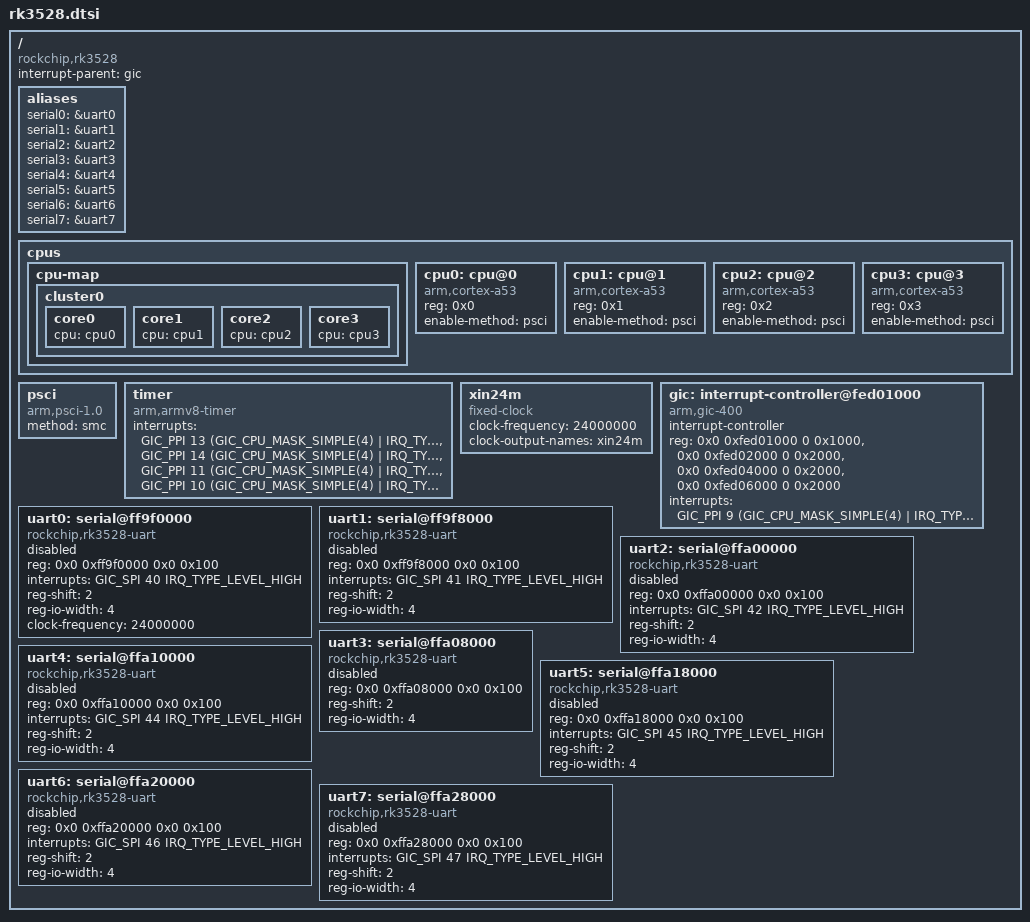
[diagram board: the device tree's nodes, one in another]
// SPDX-License-Identifier: (GPL-2.0+ OR MIT)
/*
 * Copyright (c) 2022 Rockchip Electronics Co., Ltd.
 * Copyright (c) 2024 Yao Zi <ziyao@disroot.org>
 */

#include <dt-bindings/interrupt-controller/arm-gic.h>
#include <dt-bindings/interrupt-controller/irq.h>

/ {
	compatible = "rockchip,rk3528";

	interrupt-parent = <&gic>;
	#address-cells = <2>;
	#size-cells = <2>;

	aliases {
		serial0 = &uart0;
		serial1 = &uart1;
		serial2 = &uart2;
		serial3 = &uart3;
		serial4 = &uart4;
		serial5 = &uart5;
		serial6 = &uart6;
		serial7 = &uart7;
	};

	cpus {
		#address-cells = <1>;
		#size-cells = <0>;

		cpu-map {
			cluster0 {
				core0 {
					cpu = <&cpu0>;
				};
				core1 {
					cpu = <&cpu1>;
				};
				core2 {
					cpu = <&cpu2>;
				};
				core3 {
					cpu = <&cpu3>;
				};
			};
		};

		cpu0: cpu@0 {
			device_type = "cpu";
			compatible = "arm,cortex-a53";
			reg = <0x0>;
			enable-method = "psci";
		};

		cpu1: cpu@1 {
			device_type = "cpu";
			compatible = "arm,cortex-a53";
			reg = <0x1>;
			enable-method = "psci";
		};

		cpu2: cpu@2 {
			device_type = "cpu";
			compatible = "arm,cortex-a53";
			reg = <0x2>;
			enable-method = "psci";
		};

		cpu3: cpu@3 {
			device_type = "cpu";
			compatible = "arm,cortex-a53";
			reg = <0x3>;
			enable-method = "psci";
		};
	};

	psci {
		compatible = "arm,psci-1.0", "arm,psci-0.2";
		method = "smc";
	};

	timer {
		compatible = "arm,armv8-timer";
		interrupts = <GIC_PPI 13 (GIC_CPU_MASK_SIMPLE(4) | IRQ_TYPE_LEVEL_LOW)>,
			     <GIC_PPI 14 (GIC_CPU_MASK_SIMPLE(4) | IRQ_TYPE_LEVEL_LOW)>,
			     <GIC_PPI 11 (GIC_CPU_MASK_SIMPLE(4) | IRQ_TYPE_LEVEL_LOW)>,
			     <GIC_PPI 10 (GIC_CPU_MASK_SIMPLE(4) | IRQ_TYPE_LEVEL_LOW)>;
	};

	xin24m: xin24m {
		compatible = "fixed-clock";
		#clock-cells = <0>;
		clock-frequency = <24000000>;
		clock-output-names = "xin24m";
	};

	gic: interrupt-controller@fed01000 {
		compatible = "arm,gic-400";
		#interrupt-cells = <3>;
		#address-cells = <0>;
		interrupt-controller;
		reg = <0x0 0xfed01000 0 0x1000>,
		      <0x0 0xfed02000 0 0x2000>,
		      <0x0 0xfed04000 0 0x2000>,
		      <0x0 0xfed06000 0 0x2000>;
		interrupts = <GIC_PPI 9
			(GIC_CPU_MASK_SIMPLE(4) | IRQ_TYPE_LEVEL_LOW)>;
	};

	uart0: serial@ff9f0000 {
		compatible = "rockchip,rk3528-uart", "snps,dw-apb-uart";
		reg = <0x0 0xff9f0000 0x0 0x100>;
		interrupts = <GIC_SPI 40 IRQ_TYPE_LEVEL_HIGH>;
		reg-shift = <2>;
		reg-io-width = <4>;
		clock-frequency = <24000000>;
		status = "disabled";
	};

	uart1: serial@ff9f8000 {
		compatible = "rockchip,rk3528-uart", "snps,dw-apb-uart";
		reg = <0x0 0xff9f8000 0x0 0x100>;
		interrupts = <GIC_SPI 41 IRQ_TYPE_LEVEL_HIGH>;
		reg-shift = <2>;
		reg-io-width = <4>;
		status = "disabled";
	};

	uart2: serial@ffa00000 {
		compatible = "rockchip,rk3528-uart", "snps,dw-apb-uart";
		reg = <0x0 0xffa00000 0x0 0x100>;
		interrupts = <GIC_SPI 42 IRQ_TYPE_LEVEL_HIGH>;
		reg-shift = <2>;
		reg-io-width = <4>;
		status = "disabled";
	};

	uart3: serial@ffa08000 {
		compatible = "rockchip,rk3528-uart", "snps,dw-apb-uart";
		reg = <0x0 0xffa08000 0x0 0x100>;
		reg-shift = <2>;
		reg-io-width = <4>;
		status = "disabled";
	};

	uart4: serial@ffa10000 {
		compatible = "rockchip,rk3528-uart", "snps,dw-apb-uart";
		reg = <0x0 0xffa10000 0x0 0x100>;
		interrupts = <GIC_SPI 44 IRQ_TYPE_LEVEL_HIGH>;
		reg-shift = <2>;
		reg-io-width = <4>;
		status = "disabled";
	};

	uart5: serial@ffa18000 {
		compatible = "rockchip,rk3528-uart", "snps,dw-apb-uart";
		reg = <0x0 0xffa18000 0x0 0x100>;
		interrupts = <GIC_SPI 45 IRQ_TYPE_LEVEL_HIGH>;
		reg-shift = <2>;
		reg-io-width = <4>;
		status = "disabled";
	};

	uart6: serial@ffa20000 {
		compatible = "rockchip,rk3528-uart", "snps,dw-apb-uart";
		reg = <0x0 0xffa20000 0x0 0x100>;
		interrupts = <GIC_SPI 46 IRQ_TYPE_LEVEL_HIGH>;
		reg-shift = <2>;
		reg-io-width = <4>;
		status = "disabled";
	};

	uart7: serial@ffa28000 {
		compatible = "rockchip,rk3528-uart", "snps,dw-apb-uart";
		reg = <0x0 0xffa28000 0x0 0x100>;
		interrupts = <GIC_SPI 47 IRQ_TYPE_LEVEL_HIGH>;
		reg-shift = <2>;
		reg-io-width = <4>;
		status = "disabled";
	};
};
